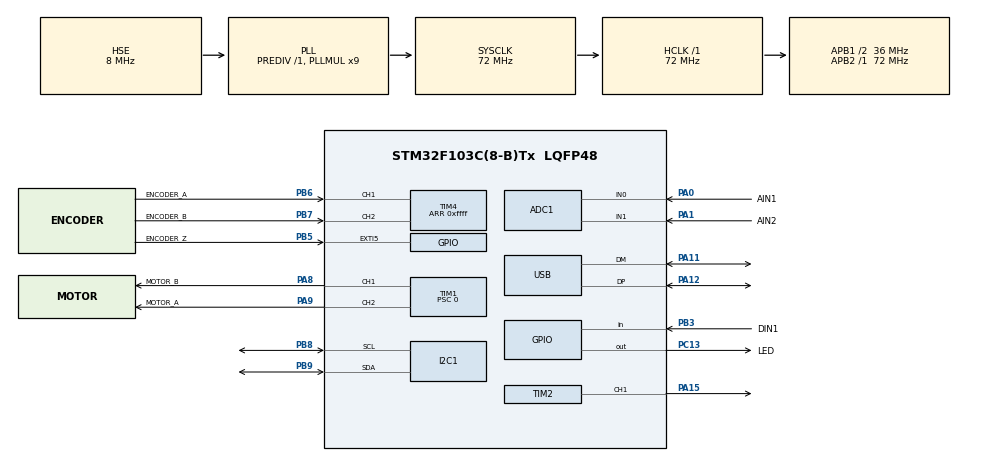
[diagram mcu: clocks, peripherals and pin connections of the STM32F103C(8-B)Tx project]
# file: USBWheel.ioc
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ADC1.Channel-2\#ChannelRegularConversion=ADC_CHANNEL_0
ADC1.Channel-3\#ChannelRegularConversion=ADC_CHANNEL_1
ADC1.ContinuousConvMode=ENABLE
ADC1.NbrOfConversion=2
ADC1.NbrOfConversionFlag=1
ADC1.Rank-2\#ChannelRegularConversion=1
ADC1.Rank-3\#ChannelRegularConversion=2
ADC1.SamplingTime-2\#ChannelRegularConversion=ADC_SAMPLETIME_239CYCLES_5
ADC1.SamplingTime-3\#ChannelRegularConversion=ADC_SAMPLETIME_239CYCLES_5
ADC1.master=1
Dma.ADC1.0.Direction=DMA_PERIPH_TO_MEMORY
Dma.ADC1.0.Instance=DMA1_Channel1
Dma.ADC1.0.MemDataAlignment=DMA_MDATAALIGN_WORD
Dma.ADC1.0.MemInc=DMA_MINC_ENABLE
Dma.ADC1.0.Mode=DMA_CIRCULAR
Dma.ADC1.0.PeriphDataAlignment=DMA_PDATAALIGN_WORD
Dma.ADC1.0.PeriphInc=DMA_PINC_DISABLE
Dma.ADC1.0.Priority=DMA_PRIORITY_LOW
Dma.Request0=ADC1
Dma.Request1=TIM2_CH1
Dma.TIM2_CH1.1.Direction=DMA_MEMORY_TO_PERIPH
Dma.TIM2_CH1.1.Instance=DMA1_Channel5
Dma.TIM2_CH1.1.MemDataAlignment=DMA_MDATAALIGN_BYTE
Dma.TIM2_CH1.1.MemInc=DMA_MINC_ENABLE
Dma.TIM2_CH1.1.Mode=DMA_CIRCULAR
Dma.TIM2_CH1.1.PeriphDataAlignment=DMA_PDATAALIGN_HALFWORD
Dma.TIM2_CH1.1.PeriphInc=DMA_PINC_DISABLE
Dma.TIM2_CH1.1.Priority=DMA_PRIORITY_LOW
I2C1.I2C_Mode=I2C_Fast
I2C1.OwnAddress=0x25
Mcu.Family=STM32F1
Mcu.Name=STM32F103C(8-B)Tx
Mcu.Package=LQFP48
NVIC.DMA1_Channel1_IRQn=true\:7\:0\:true\:false\:true\:false\:true
NVIC.DMA1_Channel5_IRQn=true\:6\:0\:true\:false\:true\:false\:true
NVIC.I2C1_ER_IRQn=true\:1\:0\:true\:false\:true\:true\:true
NVIC.I2C1_EV_IRQn=true\:0\:0\:true\:false\:true\:true\:true
NVIC.PriorityGroup=NVIC_PRIORITYGROUP_4
NVIC.TIM3_IRQn=true\:5\:0\:true\:false\:true\:true\:true
NVIC.TIM4_IRQn=true\:4\:0\:true\:false\:true\:true\:true
PA0-WKUP.GPIO_Label=AIN1
PA0-WKUP.Signal=ADCx_IN0
PA1.GPIO_Label=AIN2
PA1.Signal=ADCx_IN1
PA11.Mode=Device
PA11.Signal=USB_DM
PA12.Mode=Device
PA12.Signal=USB_DP
PA13.Mode=Serial_Wire
PA13.Signal=SYS_JTMS-SWDIO
PA14.Mode=Serial_Wire
PA14.Signal=SYS_JTCK-SWCLK
PA15.GPIO_Speed=GPIO_SPEED_FREQ_HIGH
PA15.Signal=S_TIM2_CH1_ETR
PA8.GPIO_Label=MOTOR_B
PA8.GPIO_Speed=GPIO_SPEED_FREQ_HIGH
PA8.Signal=S_TIM1_CH1
PA9.GPIO_Label=MOTOR_A
PA9.GPIO_Speed=GPIO_SPEED_FREQ_HIGH
PA9.Signal=S_TIM1_CH2
PB3.GPIO_Label=DIN1
PB3.GPIO_PuPd=GPIO_PULLUP
PB3.Signal=GPIO_Input
PB5.GPIO_Label=ENCODER_Z
PB5.GPIO_PuPd=GPIO_PULLUP
PB5.Signal=GPXTI5
PB6.GPIO_Label=ENCODER_A
PB6.GPIO_PuPd=GPIO_PULLUP
PB6.Signal=S_TIM4_CH1
PB7.GPIO_Label=ENCODER_B
PB7.GPIO_PuPd=GPIO_PULLUP
PB7.Signal=S_TIM4_CH2
PB8.Mode=I2C
PB8.Signal=I2C1_SCL
PB9.Mode=I2C
PB9.Signal=I2C1_SDA
PC13-TAMPER-RTC.GPIO_Label=LED
PC13-TAMPER-RTC.Signal=GPIO_Output
PD0-OSC_IN.Mode=HSE-External-Oscillator
PD0-OSC_IN.Signal=RCC_OSC_IN
PD1-OSC_OUT.Mode=HSE-External-Oscillator
PD1-OSC_OUT.Signal=RCC_OSC_OUT
ProjectManager.HeapSize=0x0
ProjectManager.StackSize=0x800
ProjectManager.TargetToolchain=STM32CubeIDE
RCC.ADCPresc=RCC_ADCPCLK2_DIV6
RCC.AHBFreq_Value=72000000
RCC.APB1CLKDivider=RCC_HCLK_DIV2
RCC.APB1Freq_Value=36000000
RCC.APB1TimFreq_Value=72000000
RCC.APB2Freq_Value=72000000
RCC.APB2TimFreq_Value=72000000
RCC.HCLKFreq_Value=72000000
RCC.PLLMUL=RCC_PLL_MUL9
RCC.PLLSourceVirtual=RCC_PLLSOURCE_HSE
RCC.SYSCLKFreq_VALUE=72000000
RCC.SYSCLKSource=RCC_SYSCLKSOURCE_PLLCLK
RCC.USBFreq_Value=48000000
RCC.USBPrescaler=RCC_USBCLKSOURCE_PLL_DIV1_5
SH.ADCx_IN0.0=ADC1_IN0,IN0
SH.ADCx_IN1.0=ADC1_IN1,IN1
SH.S_TIM1_CH1.0=TIM1_CH1,PWM Generation1 CH1
SH.S_TIM1_CH2.0=TIM1_CH2,PWM Generation2 CH2
SH.S_TIM2_CH1_ETR.0=TIM2_CH1,PWM Generation1 CH1
SH.S_TIM4_CH1.0=TIM4_CH1,Encoder_Interface
SH.S_TIM4_CH2.0=TIM4_CH2,Encoder_Interface
TIM1.Channel-PWM\ Generation1\ CH1=TIM_CHANNEL_1
TIM1.Channel-PWM\ Generation2\ CH2=TIM_CHANNEL_2
TIM1.Period=3599
TIM1.Prescaler=0
TIM2.Channel-PWM\ Generation1\ CH1=TIM_CHANNEL_1
TIM2.Period=89
TIM3.Period=0xFFFF
TIM3.Prescaler=72-1
TIM4.CounterMode=TIM_COUNTERMODE_CENTERALIGNED1
TIM4.EncoderMode=TIM_ENCODERMODE_TI12
TIM4.Period=0xffff
VP_TIM1_VS_ClockSourceINT.Mode=Internal
VP_TIM2_VS_ClockSourceINT.Mode=Internal
VP_TIM3_VS_ClockSourceINT.Mode=Internal
board=custom

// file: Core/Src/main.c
/* USER CODE BEGIN Header */
/**
  ******************************************************************************
  * @file           : main.c
  * @brief          : Main program body
  ******************************************************************************
  * @attention
  *
  * <h2><center>&copy; Copyright (c) 2020 STMicroelectronics.
  * All rights reserved.</center></h2>
  *
  * This software component is licensed by ST under BSD 3-Clause license,
  * the "License"; You may not use this file except in compliance with the
  * License. You may obtain a copy of the License at:
  *                        opensource.org/licenses/BSD-3-Clause
  *
  ******************************************************************************
  */
/* USER CODE END Header */

#include "main.h"

/* USER CODE BEGIN Includes */
#include <cppmain.h>

/* USER CODE END Includes */

ADC_HandleTypeDef hadc1;
DMA_HandleTypeDef hdma_adc1;

I2C_HandleTypeDef hi2c1;

TIM_HandleTypeDef htim1;
TIM_HandleTypeDef htim2;
TIM_HandleTypeDef htim3;
TIM_HandleTypeDef htim4;
DMA_HandleTypeDef hdma_tim2_ch1;

PCD_HandleTypeDef hpcd_USB_FS;

void SystemClock_Config(void);
static void MX_GPIO_Init(void);
static void MX_DMA_Init(void);
static void MX_ADC1_Init(void);
static void MX_TIM3_Init(void);
static void MX_USB_PCD_Init(void);
static void MX_TIM4_Init(void);
static void MX_I2C1_Init(void);
static void MX_TIM1_Init(void);
static void MX_TIM2_Init(void);

int main(void)
{

  /* MCU Configuration--------------------------------------------------------*/

  /* Reset of all peripherals, Initializes the Flash interface and the Systick. */
  HAL_Init();

  /* Configure the system clock */
  SystemClock_Config();

  /* Initialize all configured peripherals */
  MX_GPIO_Init();
  MX_DMA_Init();
  MX_ADC1_Init();
  MX_TIM3_Init();
  MX_USB_PCD_Init();
  MX_TIM4_Init();
  MX_I2C1_Init();
  MX_TIM1_Init();
  MX_TIM2_Init();

  /* Infinite loop */
  /* USER CODE BEGIN WHILE */
  cppmain();
  while (1)
  {
    /* USER CODE END WHILE */

  }
}

void SystemClock_Config(void)
{
  RCC_OscInitTypeDef RCC_OscInitStruct = {0};
  RCC_ClkInitTypeDef RCC_ClkInitStruct = {0};
  RCC_PeriphCLKInitTypeDef PeriphClkInit = {0};

  /** Initializes the CPU, AHB and APB busses clocks
  */
  RCC_OscInitStruct.OscillatorType = RCC_OSCILLATORTYPE_HSE;
  RCC_OscInitStruct.HSEState = RCC_HSE_ON;
  RCC_OscInitStruct.HSEPredivValue = RCC_HSE_PREDIV_DIV1;
  RCC_OscInitStruct.HSIState = RCC_HSI_ON;
  RCC_OscInitStruct.PLL.PLLState = RCC_PLL_ON;
  RCC_OscInitStruct.PLL.PLLSource = RCC_PLLSOURCE_HSE;
  RCC_OscInitStruct.PLL.PLLMUL = RCC_PLL_MUL9;
  if (HAL_RCC_OscConfig(&RCC_OscInitStruct) != HAL_OK)
  {
    Error_Handler();
  }
  /** Initializes the CPU, AHB and APB busses clocks
  */
  RCC_ClkInitStruct.ClockType = RCC_CLOCKTYPE_HCLK|RCC_CLOCKTYPE_SYSCLK
                              |RCC_CLOCKTYPE_PCLK1|RCC_CLOCKTYPE_PCLK2;
  RCC_ClkInitStruct.SYSCLKSource = RCC_SYSCLKSOURCE_PLLCLK;
  RCC_ClkInitStruct.AHBCLKDivider = RCC_SYSCLK_DIV1;
  RCC_ClkInitStruct.APB1CLKDivider = RCC_HCLK_DIV2;
  RCC_ClkInitStruct.APB2CLKDivider = RCC_HCLK_DIV1;

  if (HAL_RCC_ClockConfig(&RCC_ClkInitStruct, FLASH_LATENCY_2) != HAL_OK)
  {
    Error_Handler();
  }
  PeriphClkInit.PeriphClockSelection = RCC_PERIPHCLK_ADC|RCC_PERIPHCLK_USB;
  PeriphClkInit.AdcClockSelection = RCC_ADCPCLK2_DIV6;
  PeriphClkInit.UsbClockSelection = RCC_USBCLKSOURCE_PLL_DIV1_5;
  if (HAL_RCCEx_PeriphCLKConfig(&PeriphClkInit) != HAL_OK)
  {
    Error_Handler();
  }
}

static void MX_ADC1_Init(void)
{

  ADC_ChannelConfTypeDef sConfig = {0};

  /** Common config
  */
  hadc1.Instance = ADC1;
  hadc1.Init.ScanConvMode = ADC_SCAN_ENABLE;
  hadc1.Init.ContinuousConvMode = ENABLE;
  hadc1.Init.DiscontinuousConvMode = DISABLE;
  hadc1.Init.ExternalTrigConv = ADC_SOFTWARE_START;
  hadc1.Init.DataAlign = ADC_DATAALIGN_RIGHT;
  hadc1.Init.NbrOfConversion = 2;
  if (HAL_ADC_Init(&hadc1) != HAL_OK)
  {
    Error_Handler();
  }
  /** Configure Regular Channel
  */
  sConfig.Channel = ADC_CHANNEL_0;
  sConfig.Rank = ADC_REGULAR_RANK_1;
  sConfig.SamplingTime = ADC_SAMPLETIME_239CYCLES_5;
  if (HAL_ADC_ConfigChannel(&hadc1, &sConfig) != HAL_OK)
  {
    Error_Handler();
  }
  /** Configure Regular Channel
  */
  sConfig.Channel = ADC_CHANNEL_1;
  sConfig.Rank = ADC_REGULAR_RANK_2;
  if (HAL_ADC_ConfigChannel(&hadc1, &sConfig) != HAL_OK)
  {
    Error_Handler();
  }

}

static void MX_I2C1_Init(void)
{

  hi2c1.Instance = I2C1;
  hi2c1.Init.ClockSpeed = 400000;
  hi2c1.Init.DutyCycle = I2C_DUTYCYCLE_2;
  hi2c1.Init.OwnAddress1 = 74;
  hi2c1.Init.AddressingMode = I2C_ADDRESSINGMODE_7BIT;
  hi2c1.Init.DualAddressMode = I2C_DUALADDRESS_DISABLE;
  hi2c1.Init.OwnAddress2 = 0;
  hi2c1.Init.GeneralCallMode = I2C_GENERALCALL_DISABLE;
  hi2c1.Init.NoStretchMode = I2C_NOSTRETCH_DISABLE;
  if (HAL_I2C_Init(&hi2c1) != HAL_OK)
  {
    Error_Handler();
  }

}

static void MX_TIM1_Init(void)
{

  TIM_ClockConfigTypeDef sClockSourceConfig = {0};
  TIM_MasterConfigTypeDef sMasterConfig = {0};
  TIM_OC_InitTypeDef sConfigOC = {0};
  TIM_BreakDeadTimeConfigTypeDef sBreakDeadTimeConfig = {0};

  htim1.Instance = TIM1;
  htim1.Init.Prescaler = 0;
  htim1.Init.CounterMode = TIM_COUNTERMODE_UP;
  htim1.Init.Period = 3599;
  htim1.Init.ClockDivision = TIM_CLOCKDIVISION_DIV1;
  htim1.Init.RepetitionCounter = 0;
  htim1.Init.AutoReloadPreload = TIM_AUTORELOAD_PRELOAD_DISABLE;
  if (HAL_TIM_Base_Init(&htim1) != HAL_OK)
  {
    Error_Handler();
  }
  sClockSourceConfig.ClockSource = TIM_CLOCKSOURCE_INTERNAL;
  if (HAL_TIM_ConfigClockSource(&htim1, &sClockSourceConfig) != HAL_OK)
  {
    Error_Handler();
  }
  if (HAL_TIM_PWM_Init(&htim1) != HAL_OK)
  {
    Error_Handler();
  }
  sMasterConfig.MasterOutputTrigger = TIM_TRGO_RESET;
  sMasterConfig.MasterSlaveMode = TIM_MASTERSLAVEMODE_DISABLE;
  if (HAL_TIMEx_MasterConfigSynchronization(&htim1, &sMasterConfig) != HAL_OK)
  {
    Error_Handler();
  }
  sConfigOC.OCMode = TIM_OCMODE_PWM1;
  sConfigOC.Pulse = 0;
  sConfigOC.OCPolarity = TIM_OCPOLARITY_HIGH;
  sConfigOC.OCNPolarity = TIM_OCNPOLARITY_HIGH;
  sConfigOC.OCFastMode = TIM_OCFAST_DISABLE;
  sConfigOC.OCIdleState = TIM_OCIDLESTATE_RESET;
  sConfigOC.OCNIdleState = TIM_OCNIDLESTATE_RESET;
  if (HAL_TIM_PWM_ConfigChannel(&htim1, &sConfigOC, TIM_CHANNEL_1) != HAL_OK)
  {
    Error_Handler();
  }
  if (HAL_TIM_PWM_ConfigChannel(&htim1, &sConfigOC, TIM_CHANNEL_2) != HAL_OK)
  {
    Error_Handler();
  }
  sBreakDeadTimeConfig.OffStateRunMode = TIM_OSSR_DISABLE;
  sBreakDeadTimeConfig.OffStateIDLEMode = TIM_OSSI_DISABLE;
  sBreakDeadTimeConfig.LockLevel = TIM_LOCKLEVEL_OFF;
  sBreakDeadTimeConfig.DeadTime = 0;
  sBreakDeadTimeConfig.BreakState = TIM_BREAK_DISABLE;
  sBreakDeadTimeConfig.BreakPolarity = TIM_BREAKPOLARITY_HIGH;
  sBreakDeadTimeConfig.AutomaticOutput = TIM_AUTOMATICOUTPUT_DISABLE;
  if (HAL_TIMEx_ConfigBreakDeadTime(&htim1, &sBreakDeadTimeConfig) != HAL_OK)
  {
    Error_Handler();
  }
  HAL_TIM_MspPostInit(&htim1);

}

static void MX_TIM2_Init(void)
{

  TIM_ClockConfigTypeDef sClockSourceConfig = {0};
  TIM_MasterConfigTypeDef sMasterConfig = {0};
  TIM_OC_InitTypeDef sConfigOC = {0};

  htim2.Instance = TIM2;
  htim2.Init.Prescaler = 0;
  htim2.Init.CounterMode = TIM_COUNTERMODE_UP;
  htim2.Init.Period = 89;
  htim2.Init.ClockDivision = TIM_CLOCKDIVISION_DIV1;
  htim2.Init.AutoReloadPreload = TIM_AUTORELOAD_PRELOAD_DISABLE;
  if (HAL_TIM_Base_Init(&htim2) != HAL_OK)
  {
    Error_Handler();
  }
  sClockSourceConfig.ClockSource = TIM_CLOCKSOURCE_INTERNAL;
  if (HAL_TIM_ConfigClockSource(&htim2, &sClockSourceConfig) != HAL_OK)
  {
    Error_Handler();
  }
  if (HAL_TIM_PWM_Init(&htim2) != HAL_OK)
  {
    Error_Handler();
  }
  sMasterConfig.MasterOutputTrigger = TIM_TRGO_RESET;
  sMasterConfig.MasterSlaveMode = TIM_MASTERSLAVEMODE_DISABLE;
  if (HAL_TIMEx_MasterConfigSynchronization(&htim2, &sMasterConfig) != HAL_OK)
  {
    Error_Handler();
  }
  sConfigOC.OCMode = TIM_OCMODE_PWM1;
  sConfigOC.Pulse = 0;
  sConfigOC.OCPolarity = TIM_OCPOLARITY_HIGH;
  sConfigOC.OCFastMode = TIM_OCFAST_DISABLE;
  if (HAL_TIM_PWM_ConfigChannel(&htim2, &sConfigOC, TIM_CHANNEL_1) != HAL_OK)
  {
    Error_Handler();
  }
  HAL_TIM_MspPostInit(&htim2);

}

static void MX_TIM3_Init(void)
{

  TIM_ClockConfigTypeDef sClockSourceConfig = {0};
  TIM_MasterConfigTypeDef sMasterConfig = {0};

  htim3.Instance = TIM3;
  htim3.Init.Prescaler = 72-1;
  htim3.Init.CounterMode = TIM_COUNTERMODE_UP;
  htim3.Init.Period = 0xFFFF;
  htim3.Init.ClockDivision = TIM_CLOCKDIVISION_DIV1;
  htim3.Init.AutoReloadPreload = TIM_AUTORELOAD_PRELOAD_DISABLE;
  if (HAL_TIM_Base_Init(&htim3) != HAL_OK)
  {
    Error_Handler();
  }
  sClockSourceConfig.ClockSource = TIM_CLOCKSOURCE_INTERNAL;
  if (HAL_TIM_ConfigClockSource(&htim3, &sClockSourceConfig) != HAL_OK)
  {
    Error_Handler();
  }
  sMasterConfig.MasterOutputTrigger = TIM_TRGO_RESET;
  sMasterConfig.MasterSlaveMode = TIM_MASTERSLAVEMODE_DISABLE;
  if (HAL_TIMEx_MasterConfigSynchronization(&htim3, &sMasterConfig) != HAL_OK)
  {
    Error_Handler();
  }

}

static void MX_TIM4_Init(void)
{

  TIM_Encoder_InitTypeDef sConfig = {0};
  TIM_MasterConfigTypeDef sMasterConfig = {0};

  htim4.Instance = TIM4;
  htim4.Init.Prescaler = 0;
  htim4.Init.CounterMode = TIM_COUNTERMODE_CENTERALIGNED1;
  htim4.Init.Period = 0xffff;
  htim4.Init.ClockDivision = TIM_CLOCKDIVISION_DIV1;
  htim4.Init.AutoReloadPreload = TIM_AUTORELOAD_PRELOAD_DISABLE;
  sConfig.EncoderMode = TIM_ENCODERMODE_TI12;
  sConfig.IC1Polarity = TIM_ICPOLARITY_RISING;
  sConfig.IC1Selection = TIM_ICSELECTION_DIRECTTI;
  sConfig.IC1Prescaler = TIM_ICPSC_DIV1;
  sConfig.IC1Filter = 0;
  sConfig.IC2Polarity = TIM_ICPOLARITY_RISING;
  sConfig.IC2Selection = TIM_ICSELECTION_DIRECTTI;
  sConfig.IC2Prescaler = TIM_ICPSC_DIV1;
  sConfig.IC2Filter = 0;
  if (HAL_TIM_Encoder_Init(&htim4, &sConfig) != HAL_OK)
  {
    Error_Handler();
  }
  sMasterConfig.MasterOutputTrigger = TIM_TRGO_RESET;
  sMasterConfig.MasterSlaveMode = TIM_MASTERSLAVEMODE_DISABLE;
  if (HAL_TIMEx_MasterConfigSynchronization(&htim4, &sMasterConfig) != HAL_OK)
  {
    Error_Handler();
  }

}

static void MX_USB_PCD_Init(void)
{

  /* USER CODE BEGIN USB_Init 0 */
#if false
  /* USER CODE END USB_Init 0 */

  hpcd_USB_FS.Instance = USB;
  hpcd_USB_FS.Init.dev_endpoints = 8;
  hpcd_USB_FS.Init.speed = PCD_SPEED_FULL;
  hpcd_USB_FS.Init.low_power_enable = DISABLE;
  hpcd_USB_FS.Init.lpm_enable = DISABLE;
  hpcd_USB_FS.Init.battery_charging_enable = DISABLE;
  if (HAL_PCD_Init(&hpcd_USB_FS) != HAL_OK)
  {
    Error_Handler();
  }
  /* USER CODE BEGIN USB_Init 2 */
#endif
  /* USER CODE END USB_Init 2 */

}

static void MX_DMA_Init(void)
{

  /* DMA controller clock enable */
  __HAL_RCC_DMA1_CLK_ENABLE();

  /* DMA interrupt init */
  /* DMA1_Channel1_IRQn interrupt configuration */
  HAL_NVIC_SetPriority(DMA1_Channel1_IRQn, 7, 0);
  HAL_NVIC_EnableIRQ(DMA1_Channel1_IRQn);
  /* DMA1_Channel5_IRQn interrupt configuration */
  HAL_NVIC_SetPriority(DMA1_Channel5_IRQn, 6, 0);
  HAL_NVIC_EnableIRQ(DMA1_Channel5_IRQn);

}

static void MX_GPIO_Init(void)
{
  GPIO_InitTypeDef GPIO_InitStruct = {0};

  /* GPIO Ports Clock Enable */
  __HAL_RCC_GPIOC_CLK_ENABLE();
  __HAL_RCC_GPIOD_CLK_ENABLE();
  __HAL_RCC_GPIOA_CLK_ENABLE();
  __HAL_RCC_GPIOB_CLK_ENABLE();

  /*Configure GPIO pin Output Level */
  HAL_GPIO_WritePin(LED_GPIO_Port, LED_Pin, GPIO_PIN_RESET);

  /*Configure GPIO pin : LED_Pin */
  GPIO_InitStruct.Pin = LED_Pin;
  GPIO_InitStruct.Mode = GPIO_MODE_OUTPUT_PP;
  GPIO_InitStruct.Pull = GPIO_NOPULL;
  GPIO_InitStruct.Speed = GPIO_SPEED_FREQ_LOW;
  HAL_GPIO_Init(LED_GPIO_Port, &GPIO_InitStruct);

  /*Configure GPIO pin : DIN1_Pin */
  GPIO_InitStruct.Pin = DIN1_Pin;
  GPIO_InitStruct.Mode = GPIO_MODE_INPUT;
  GPIO_InitStruct.Pull = GPIO_PULLUP;
  HAL_GPIO_Init(DIN1_GPIO_Port, &GPIO_InitStruct);

  /*Configure GPIO pin : ENCODER_Z_Pin */
  GPIO_InitStruct.Pin = ENCODER_Z_Pin;
  GPIO_InitStruct.Mode = GPIO_MODE_IT_RISING;
  GPIO_InitStruct.Pull = GPIO_PULLUP;
  HAL_GPIO_Init(ENCODER_Z_GPIO_Port, &GPIO_InitStruct);

}

void Error_Handler(void)
{
  /* USER CODE BEGIN Error_Handler_Debug */
  /* User can add his own implementation to report the HAL error return state */
	while (1)
	{
		HAL_GPIO_TogglePin(GPIOC, GPIO_PIN_13);
		HAL_Delay(5000);
	}
  /* USER CODE END Error_Handler_Debug */
}

/************************ (C) COPYRIGHT STMicroelectronics *****END OF FILE****/
